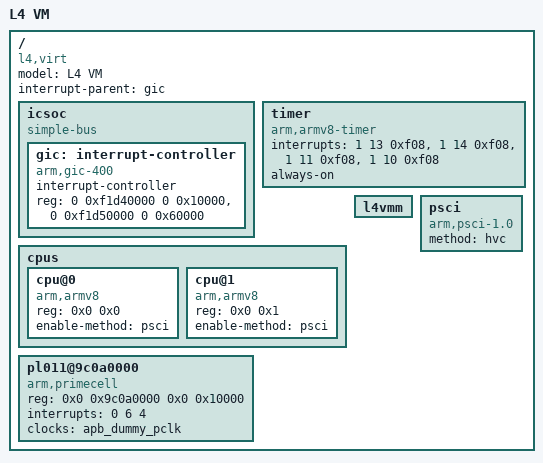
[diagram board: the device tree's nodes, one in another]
/*
 * Device tree for a virtual machine without any hardware pass-through.
 */

/dts-v1/;
/include/ "skeleton64.dtsi"
/include/ "vmm-devices-arm.dtsi"

/ {
    model = "L4 VM";
    compatible = "l4,virt", "linux,dummy-virt";

    interrupt-parent = <&gic>;

    icsoc {
        compatible = "simple-bus";
        #address-cells = <2>;
        #size-cells = <2>;
        ranges;

        /* Uvmm will adapt the compatible string depending on the present gic
         * version. It expects reg entries that provide enough space for the
         * Cpu/Dist interface for gicv2 (at least 0x1000, 0x1000) or the
         * Dist/Redist interface for gicv3 (0x10000, 0x20000 * number of cpus).
         * The entries provided here support any gicv2 setup or a gicv3 setup
         * with one Cpu.
         */
        gic: interrupt-controller {
            compatible = "arm,gic-400", "arm,cortex-a15-gic", "arm,cortex-a9-gic";
            #interrupt-cells = <3>;
            #address-cells = <0>;
            interrupt-controller;
            reg = <0 0xf1d40000 0 0x10000>,
                  <0 0xf1d50000 0 0x60000>;
            };
    };

    timer {
      compatible = "arm,armv8-timer";
      interrupts = <1 13 0xf08>,
                   <1 14 0xf08>,
                   <1 11 0xf08>,
                   <1 10 0xf08>;
      always-on;
    };

    cpus {
      #address-cells = <2>;
      #size-cells = <0>;

      cpu@0 {
        device_type = "cpu";
        compatible = "arm,armv8";
        reg = <0x0 0x0>;
        enable-method = "psci";
      };

      cpu@1 {
        device_type = "cpu";
        compatible = "arm,armv8";
        reg = <0x0 0x1>;
        enable-method = "psci";
      };
    };

    l4vmm {
        ranges = <0x0 0x0 0xf0000000 0x21000>;
    };

    psci {
        compatible = "arm,psci-1.0";
        method = "hvc";
    };

    pl011@9c0a0000 {
            compatible = "arm,primecell", "arm,pl011";
            reg = <0x0 0x9c0a0000 0x0 0x10000>;
            interrupts = <0 6 4>;
            clocks = <&apb_dummy_pclk>;
            clock-names = "apb_pclk";
    };
};
